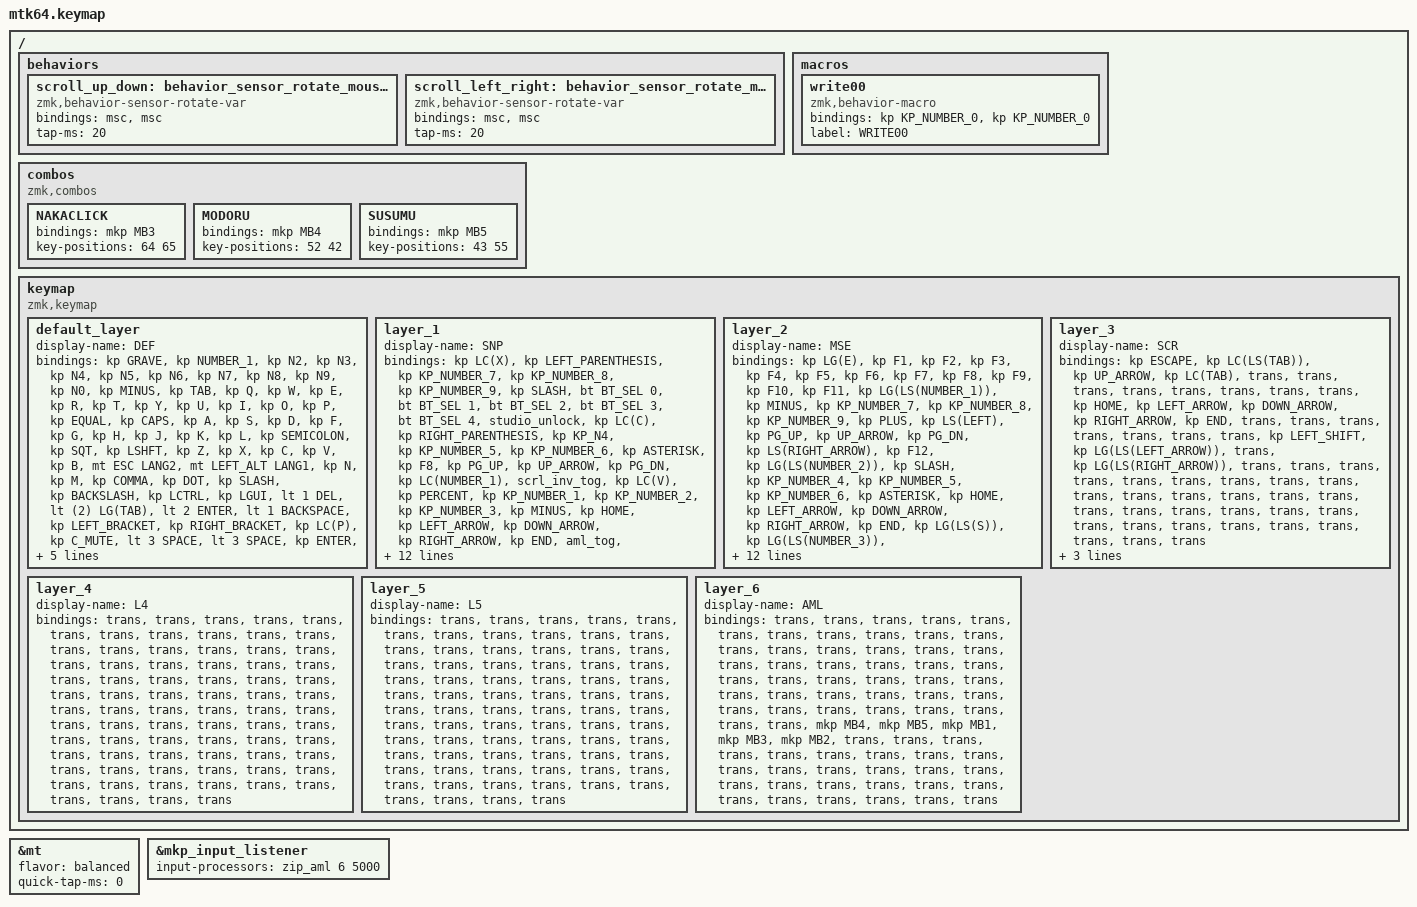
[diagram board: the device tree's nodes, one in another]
#include <input/processors.dtsi>
#include <behaviors.dtsi>
#include <dt-bindings/zmk/bt.h>
#include <dt-bindings/zmk/keys.h>
#include <dt-bindings/zmk/pointing.h>
#include "keycode_japanese.h"

// スクロール量の設定

#define ZMK_POINTING_DEFAULT_SCRL_VAL 100

&mt {
    flavor = "balanced";
    quick-tap-ms = <0>;
};

&mkp_input_listener { input-processors = <&zip_aml 6 5000>; };

/ {
    behaviors {
        // 垂直スクロール用のbehaviorの設定

        scroll_up_down: behavior_sensor_rotate_mouse_wheel_up_down {
            compatible = "zmk,behavior-sensor-rotate-var";
            #sensor-binding-cells = <2>;
            bindings = <&msc>, <&msc>;

            tap-ms = <20>; // スクロールのタップ時間
        };

        // 水平スクロール用のbehaviorの設定

        scroll_left_right: behavior_sensor_rotate_mouse_wheel_left_right {
            compatible = "zmk,behavior-sensor-rotate-var";
            #sensor-binding-cells = <2>;
            bindings = <&msc>, <&msc>;

            tap-ms = <20>; // スクロールのタップ時間
        };
    };
};

/ {
    macros {
        write00: write00 {
            compatible = "zmk,behavior-macro";
            #binding-cells = <0>;
            bindings = <&kp KP_NUMBER_0 &kp KP_NUMBER_0>;
            label = "WRITE00";
        };
    };

    combos {
        compatible = "zmk,combos";

        NAKACLICK {
            bindings = <&mkp MB3>;
            key-positions = <64 65>;
        };

        MODORU {
            bindings = <&mkp MB4>;
            key-positions = <52 42>;
        };

        SUSUMU {
            bindings = <&mkp MB5>;
            key-positions = <43 55>;
        };
    };

    keymap {
        compatible = "zmk,keymap";

        default_layer {
            display-name = "DEF";
            bindings = <
&kp GRAVE  &kp NUMBER_1  &kp N2  &kp N3  &kp N4  &kp N5  &kp N6  &kp N7  &kp N8  &kp N9  &kp N0  &kp MINUS  &kp TAB  &kp Q  &kp W  &kp E  &kp R  &kp T  &kp Y  &kp U  &kp I  &kp O  &kp P  &kp EQUAL  &kp CAPS  &kp A  &kp S  &kp D  &kp F  &kp G  &kp H  &kp J  &kp K  &kp L  &kp SEMICOLON  &kp SQT  &kp LSHFT  &kp Z  &kp X  &kp C  &kp V  &kp B  &mt ESC LANG2  &mt LEFT_ALT LANG1  &kp N  &kp M  &kp COMMA  &kp DOT  &kp SLASH  &kp BACKSLASH  &kp LCTRL  &kp LGUI  &lt 1 DEL  &lt (2) LG(TAB)  &lt 2 ENTER  &lt 1 BACKSPACE  &kp LEFT_BRACKET  &kp RIGHT_BRACKET  &kp LC(P)  &kp C_MUTE  &lt 3 SPACE  &lt 3 SPACE  &kp ENTER  &tog 2  &mkp LCLK  &mkp RCLK  &mo 1  &mo 2  &mo 3  &mo 1  &mo 2  &mo 3  &mo 1  &mo 2  &mo 3
            >;

            sensor-bindings =
                <&inc_dec_kp (LC(MINUS)) LC(EQUAL)>,
                <&inc_dec_kp C_VOL_DN C_VOL_UP>;
        };

        layer_1 {
            display-name = "SNP";
            bindings = <
&kp LC(X)  &kp LEFT_PARENTHESIS  &kp KP_NUMBER_7  &kp KP_NUMBER_8  &kp KP_NUMBER_9  &kp SLASH  &bt BT_SEL 0  &bt BT_SEL 1  &bt BT_SEL 2  &bt BT_SEL 3  &bt BT_SEL 4  &studio_unlock  &kp LC(C)  &kp RIGHT_PARENTHESIS  &kp KP_N4  &kp KP_NUMBER_5  &kp KP_NUMBER_6  &kp ASTERISK  &kp F8  &kp PG_UP  &kp UP_ARROW  &kp PG_DN  &kp LC(NUMBER_1)  &scrl_inv_tog  &kp LC(V)  &kp PERCENT  &kp KP_NUMBER_1  &kp KP_NUMBER_2  &kp KP_NUMBER_3  &kp MINUS  &kp HOME  &kp LEFT_ARROW  &kp DOWN_ARROW  &kp RIGHT_ARROW  &kp END  &aml_tog  &kp LC(LA(V))  &kp COMMA  &write00  &kp KP_NUMBER_0  &kp PERIOD  &kp PLUS  &kp EQUAL  &mkp MB4  &mkp MB5  &mkp MB1  &mkp MB3  &mkp MB2  &bt BT_CLR_ALL  &cpi_inc  &kp F7  &kp F10  &trans  &trans  &trans  &trans  &trans  &cpi_dec  &kp F2  &kp F4  &trans  &trans  &trans  &trans  &trans  &trans  &trans  &trans  &trans  &trans  &trans  &trans  &trans  &trans  &trans
            >;

            sensor-bindings =
                <&inc_dec_kp UP_ARROW DOWN_ARROW>,
                <&inc_dec_kp LEFT_ARROW RIGHT_ARROW>;
        };

        layer_2 {
            display-name = "MSE";
            bindings = <
&kp LG(E)  &kp F1  &kp F2  &kp F3  &kp F4  &kp F5  &kp F6  &kp F7  &kp F8  &kp F9  &kp F10  &kp F11  &kp LG(LS(NUMBER_1))  &kp MINUS  &kp KP_NUMBER_7  &kp KP_NUMBER_8  &kp KP_NUMBER_9  &kp PLUS  &kp LS(LEFT)  &kp PG_UP  &kp UP_ARROW  &kp PG_DN  &kp LS(RIGHT_ARROW)  &kp F12  &kp LG(LS(NUMBER_2))  &kp SLASH  &kp KP_NUMBER_4  &kp KP_NUMBER_5  &kp KP_NUMBER_6  &kp ASTERISK  &kp HOME  &kp LEFT_ARROW  &kp DOWN_ARROW  &kp RIGHT_ARROW  &kp END  &kp LG(LS(S))  &kp LG(LS(NUMBER_3))  &mt LEFT_SHIFT KP_NUMBER_0  &kp KP_NUMBER_1  &kp KP_NUMBER_2  &kp KP_NUMBER_3  &kp PERIOD  &kp EQUAL  &mkp MB4  &mkp MB5  &mkp MB1  &mkp MB3  &mkp MB2  &kp LS(UP_ARROW)  &kp LG(PRINTSCREEN)  &kp LS(LG(NUMBER_4))  &kp LEFT_GUI  &trans  &trans  &trans  &trans  &trans  &trans  &trans  &trans  &trans  &trans  &trans  &trans  &trans  &trans  &trans  &trans  &trans  &trans  &trans  &trans  &trans  &trans  &trans
            >;

            sensor-bindings =
                <&inc_dec_kp LS(TAB) TAB>,
                <&inc_dec_kp PG_UP PG_DN>;
        };

        layer_3 {
            display-name = "SCR";
            bindings = <
&kp ESCAPE  &kp LC(LS(TAB))  &kp UP_ARROW  &kp LC(TAB)  &trans  &trans  &trans  &trans  &trans  &trans  &trans  &trans  &kp HOME  &kp LEFT_ARROW  &kp DOWN_ARROW  &kp RIGHT_ARROW  &kp END  &trans  &trans  &trans  &trans  &trans  &trans  &trans  &kp LEFT_SHIFT  &kp LG(LS(LEFT_ARROW))  &trans  &kp LG(LS(RIGHT_ARROW))  &trans  &trans  &trans  &trans  &trans  &trans  &trans  &trans  &trans  &trans  &trans  &trans  &trans  &trans  &trans  &trans  &trans  &trans  &trans  &trans  &trans  &trans  &trans  &trans  &trans  &trans  &trans  &trans  &trans  &trans
            >;

            sensor-bindings = <
                &scroll_left_right SCRL_LEFT SCRL_RIGHT
                &scroll_up_down SCRL_UP SCRL_DOWN
            >;
        };

        layer_4 {
            display-name = "L4";
            bindings = <
&trans  &trans  &trans  &trans  &trans  &trans  &trans  &trans  &trans  &trans  &trans  &trans  &trans  &trans  &trans  &trans  &trans  &trans  &trans  &trans  &trans  &trans  &trans  &trans  &trans  &trans  &trans  &trans  &trans  &trans  &trans  &trans  &trans  &trans  &trans  &trans  &trans  &trans  &trans  &trans  &trans  &trans  &trans  &trans  &trans  &trans  &trans  &trans  &trans  &trans  &trans  &trans  &trans  &trans  &trans  &trans  &trans  &trans  &trans  &trans  &trans  &trans  &trans  &trans  &trans  &trans  &trans  &trans  &trans  &trans  &trans  &trans  &trans  &trans  &trans
            >;
        };

        layer_5 {
            display-name = "L5";
            bindings = <
&trans  &trans  &trans  &trans  &trans  &trans  &trans  &trans  &trans  &trans  &trans  &trans  &trans  &trans  &trans  &trans  &trans  &trans  &trans  &trans  &trans  &trans  &trans  &trans  &trans  &trans  &trans  &trans  &trans  &trans  &trans  &trans  &trans  &trans  &trans  &trans  &trans  &trans  &trans  &trans  &trans  &trans  &trans  &trans  &trans  &trans  &trans  &trans  &trans  &trans  &trans  &trans  &trans  &trans  &trans  &trans  &trans  &trans  &trans  &trans  &trans  &trans  &trans  &trans  &trans  &trans  &trans  &trans  &trans  &trans  &trans  &trans  &trans  &trans  &trans
            >;
        };

        layer_6 {
            display-name = "AML";
            bindings = <
&trans  &trans  &trans  &trans  &trans  &trans  &trans  &trans  &trans  &trans  &trans  &trans  &trans  &trans  &trans  &trans  &trans  &trans  &trans  &trans  &trans  &trans  &trans  &trans  &trans  &trans  &trans  &trans  &trans  &trans  &trans  &trans  &trans  &trans  &trans  &trans  &trans  &trans  &trans  &trans  &trans  &trans  &trans  &mkp MB4  &mkp MB5  &mkp MB1  &mkp MB3  &mkp MB2  &trans  &trans  &trans  &trans  &trans  &trans  &trans  &trans  &trans  &trans  &trans  &trans  &trans  &trans  &trans  &trans  &trans  &trans  &trans  &trans  &trans  &trans  &trans  &trans  &trans  &trans  &trans
            >;
        };
    };
};
